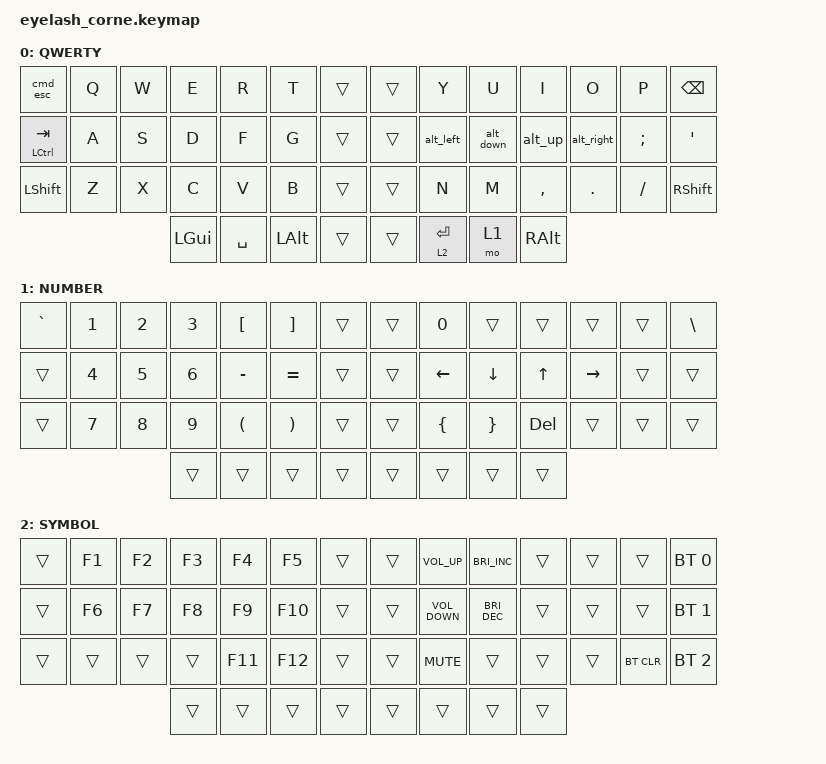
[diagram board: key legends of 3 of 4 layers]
#include <behaviors.dtsi>
#include <dt-bindings/zmk/bt.h>
#include <dt-bindings/zmk/keys.h>
#include <dt-bindings/zmk/mouse.h>
#include <dt-bindings/zmk/outputs.h>
#include <dt-bindings/zmk/rgb.h>

/ {
    behaviors {
        alt_left: alt_left {
            compatible = "zmk,behavior-mod-morph";
            label = "ALT_LEFT";
            bindings = <&kp H>, <&kp LEFT>;

            #binding-cells = <0>;
            mods = <(MOD_RALT)>;
            keep-mods = <(MOD_RALT)>;
        };

        alt_right: alt_right {
            compatible = "zmk,behavior-mod-morph";
            label = "ALT_RIGHT";
            bindings = <&kp L>, <&kp RIGHT>;

            #binding-cells = <0>;
            mods = <(MOD_RALT)>;
            keep-mods = <(MOD_RALT)>;
        };

        alt_down: alt_down {
            compatible = "zmk,behavior-mod-morph";
            label = "ALT_DOWN";
            bindings = <&kp J>, <&kp DOWN>;

            #binding-cells = <0>;
            mods = <(MOD_RALT)>;
            keep-mods = <(MOD_RALT)>;
        };

        alt_up: alt_up {
            compatible = "zmk,behavior-mod-morph";
            label = "ALT_UP";
            bindings = <&kp K>, <&kp UP_ARROW>;

            #binding-cells = <0>;
            mods = <(MOD_RALT)>;
            keep-mods = <(MOD_RALT)>;
        };

        cmd_esc: cmd_esc {
            compatible = "zmk,behavior-mod-morph";
            label = "CMD_ESC";
            bindings = <&kp ESCAPE>, <&kp GRAVE>;

            #binding-cells = <0>;
            mods = <(MOD_LGUI)>;
            keep-mods = <(MOD_LGUI)>;
        };
    };

    rgb_encoder: rgb_encoder {
        compatible = "zmk,behavior-sensor-rotate";
        #sensor-binding-cells = <0>;
        bindings = <&rgb_ug RGB_BRI>, <&rgb_ug RGB_BRD>;
    };

    keymap {
        compatible = "zmk,keymap";

        default_layer {
            display-name = "QWERTY";

            bindings = <
&cmd_esc       &kp Q  &kp W  &kp E     &kp R        &kp T        &trans        &trans        &kp Y        &kp U      &kp I      &kp O       &kp P     &kp BSPC
&mt LCTRL TAB  &kp A  &kp S  &kp D     &kp F        &kp G        &trans        &trans        &alt_left    &alt_down  &alt_up    &alt_right  &kp SEMI  &kp SQT
&kp LSHFT      &kp Z  &kp X  &kp C     &kp V        &kp B        &trans        &trans        &kp N        &kp M      &kp COMMA  &kp DOT     &kp FSLH  &kp RIGHT_SHIFT
                             &kp LGUI  &kp SPACE  &kp LALT    &trans        &trans        &lt 2 ENTER  &mo 1      &kp RALT
            >;

            sensor-bindings = <&inc_dec_kp C_VOLUME_UP C_VOLUME_DOWN>;
        };

        lower_layer {
            display-name = "NUMBER";
            bindings = <
&kp GRAVE  &kp N1  &kp N2  &kp N3  &kp LEFT_BRACKET      &kp RIGHT_BRACKET        &trans        &trans        &kp N0    &trans    &trans      &trans     &trans  &kp BACKSLASH
&trans     &kp N4  &kp N5  &kp N6  &kp MINUS             &kp EQUAL                &trans        &trans        &kp LEFT  &kp DOWN  &kp UP      &kp RIGHT  &trans  &trans
&trans     &kp N7  &kp N8  &kp N9  &kp LEFT_PARENTHESIS  &kp RIGHT_PARENTHESIS    &trans        &trans        &kp LBRC  &kp RBRC  &kp DELETE  &trans     &trans  &trans
                           &trans  &trans                &trans                   &trans        &trans        &trans    &trans    &trans
            >;

            sensor-bindings = <&inc_dec_kp PG_UP PG_DN>;
        };

        raise_layer {
            display-name = "SYMBOL";
            bindings = <
&trans  &kp F1  &kp F2  &kp F3  &kp F4   &kp F5     &trans        &trans        &kp C_VOLUME_UP    &kp C_BRIGHTNESS_INC  &trans  &trans  &trans      &bt BT_SEL 0
&trans  &kp F6  &kp F7  &kp F8  &kp F9   &kp F10    &trans        &trans        &kp C_VOLUME_DOWN  &kp C_BRIGHTNESS_DEC  &trans  &trans  &trans      &bt BT_SEL 1
&trans  &trans  &trans  &trans  &kp F11  &kp F12    &trans        &trans        &kp K_MUTE         &trans                &trans  &trans  &bt BT_CLR  &bt BT_SEL 2
                        &trans  &trans   &trans     &trans        &trans        &trans             &trans                &trans
            >;

            sensor-bindings = <&inc_dec_kp PG_UP PG_DN>;
        };

        layer_3 {
            display-name = "Fn";
            bindings = <
&trans  &kp F1      &kp F2      &kp F3       &kp F4     &kp F5                         &trans        &trans        &kp F6       &kp F7     &kp F8       &kp F9      &kp F10          &kp F11
&trans  &trans      &mkp LCLK   &mkp MCLK    &mkp RCLK  &mkp MB4               &trans        &trans        &bootloader  &mkp LCLK  &mkp MCLK    &mkp RCLK   &kp PRINTSCREEN  &kp F12
&trans  &sys_reset  &trans      &bootloader  &trans     &mkp MB5 &kp C_MUTE            &trans        &trans        &trans       &trans     &bootloader  &sys_reset  &kp SCROLLLOCK   &kp PAUSE_BREAK
                                &trans      &trans      &trans                   &trans        &trans        &trans       &trans     &trans
            >;

            sensor-bindings = <&rgb_encoder>;
        };
    };
};
